# f28p65x_ecap_signal_monitoring_regs register map
Vendor: Texas Instruments
Peripheral module from a debugger description file (folder C2000).
Address unit: 16 bits
Registers are 32-bit, read-write, no defined reset value unless marked. A register's access mark holds for its fields unless they carry their own. Offsets are as the file gives them; lines under a group give offsets from that group; [hi:lo] are bit positions; {n}, {i} and the like mark numbered series; 'fields as' and 'values as' point back to an identical list; <NAME> marks a mode.

## ECAP_SIGNAL_MONITORING — ECAP SIGNAL MONITORING Registers
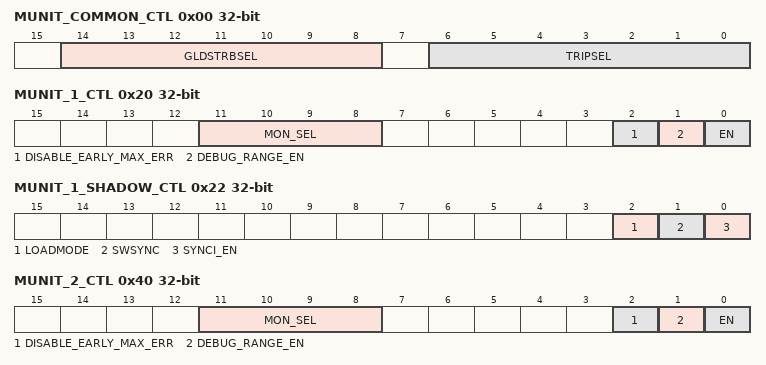
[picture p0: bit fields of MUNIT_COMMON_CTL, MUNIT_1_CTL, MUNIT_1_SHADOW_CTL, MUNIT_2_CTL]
0x00 MUNIT_COMMON_CTL — Control registers for monitoring unit {#}
  [14:8] GLDSTRBSEL — Global Load strobe select
  [6:0] TRIPSEL — Trip signal select
0x20 MUNIT_1_CTL — Control registers for monitoring unit 1
  [11:8] MON_SEL — Selects type of monitoring
  [2] DISABLE_EARLY_MAX_ERR — Disable early max error check
  [1] DEBUG_RANGE_EN — Debug enable to aquire the range of check being done
  [0] EN — Enable bit
0x22 MUNIT_1_SHADOW_CTL — Shadow control registers for monitoring unit 1
  [2] LOADMODE
  [1] SWSYNC — SW sync to copy shadow to active Min and Max registers
  [0] SYNCI_EN — Enable for shadowing on Min and Max Registers
0x28 MUNIT_1_MIN — Min value for monitoring unit 1
  [31:0] MIN_VALUE — Mimum value for monitoring
0x2A MUNIT_1_MAX — Max value for monitoring unit 1
  [31:0] MAX_VALUE — Maximum value for monitoring
0x2C MUNIT_1_MIN_SHADOW — Shadow register for Min value of monitoring unit 1
  [31:0] MIN_VALUE_SHADOW — Shadow Mimum value for monitoring
0x2E MUNIT_1_MAX_SHADOW — Shadow register for Max value of monitoring unit 1
  [31:0] MAX_VALUE_SHADOW — Shadow Maximum value for monitoring
0x30 MUNIT_1_DEBUG_RANGE_MIN ro — Observed Min value of check being enabled on minotoring unit 1
  [31:0] MIN_VALUE — Observed min value
0x32 MUNIT_1_DEBUG_RANGE_MAX ro — Observed Max value of check being enabled on minotoring unit 1
  [31:0] MAX_VALUE — Observed max value
0x40 MUNIT_2_CTL — Control registers for monitoring unit 2
  fields as MUNIT_1_CTL
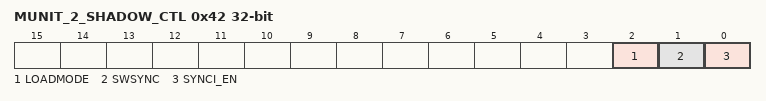
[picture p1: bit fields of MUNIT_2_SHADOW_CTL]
0x42 MUNIT_2_SHADOW_CTL — Shadow control registers for monitoring unit 2
  fields as MUNIT_1_SHADOW_CTL
0x48 MUNIT_2_MIN — Min value for monitoring unit 2
  [31:0] MIN_VALUE — Mimum value for monitoring
0x4A MUNIT_2_MAX — Max value for monitoring unit 2
  [31:0] MAX_VALUE — Maximum value for monitoring
0x4C MUNIT_2_MIN_SHADOW — Shadow register for Min value of monitoring unit 2
  [31:0] MIN_VALUE_SHADOW — Shadow Mimum value for monitoring
0x4E MUNIT_2_MAX_SHADOW — Shadow register for Max value of monitoring unit 2
  [31:0] MAX_VALUE_SHADOW — Shadow Maximum value for monitoring
0x50 MUNIT_2_DEBUG_RANGE_MIN ro — Observed Min value of check being enabled on minotoring unit 2
  [31:0] MIN_VALUE — Observed min value
0x52 MUNIT_2_DEBUG_RANGE_MAX ro — Observed Max value of check being enabled on minotoring unit 2
  [31:0] MAX_VALUE — Observed max value
